# ESP32-S31 register map
Vendor: ESPRESSIF SYSTEMS (SHANGHAI) CO., LTD.; Series: ESP32 S-Series; File version: 1
CPU: RV32IMAFC r0p0, little endian, no MPU, FPU, 0 interrupt priority bits
Address unit: 32 bits
Registers are 32-bit, read-write, reset 0x0 unless marked. A register's access mark holds for its fields unless they carry their own. Offsets are from the block's base; [hi:lo] are bit positions; {n}, {i} and the like mark numbered series.

## DMA2D — DMA2D Peripheral
Base 0x20346000
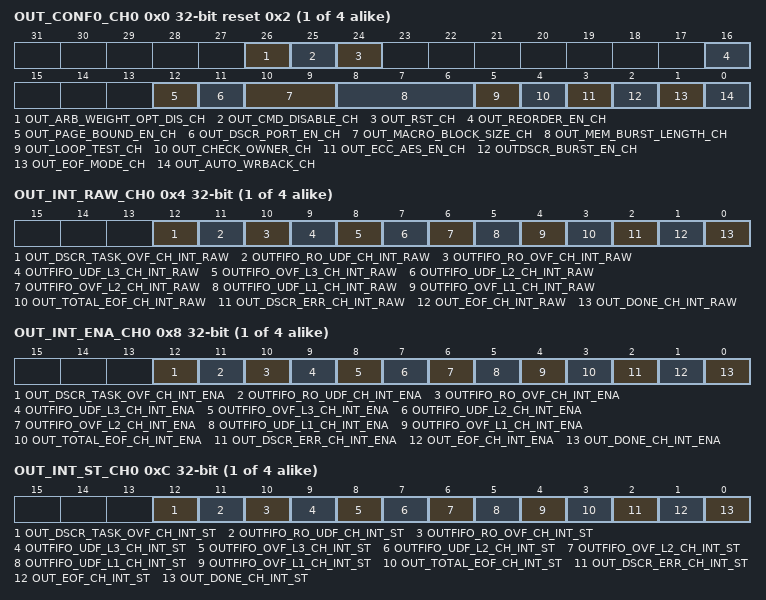
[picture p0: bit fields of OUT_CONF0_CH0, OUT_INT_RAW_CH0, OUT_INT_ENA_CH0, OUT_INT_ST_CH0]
{0x0+0x100*i} OUT_CONF0_CH{i} (i=0..3) reset 0x2 — Configures the tx direction of channel {i}
  [26] OUT_ARB_WEIGHT_OPT_DIS_CH — Set this bit to 1 to disable arbiter optimum weight function.
  [25] OUT_CMD_DISABLE_CH — Write 1 before reset and write 0 after reset
  [24] OUT_RST_CH — Write 1 then write 0 to this bit to reset TX channel
  [16] OUT_REORDER_EN_CH — Enable TX channel 0 macro block reorder when set to 1, only channel0 have this selection
  [12] OUT_PAGE_BOUND_EN_CH — Set this bit to 1 to make sure AXI read data don't cross the address boundary which define by mem_burst_length
  [11] OUT_DSCR_PORT_EN_CH — Set this bit to 1 to obtain descriptor from IP port
  [10:9] OUT_MACRO_BLOCK_SIZE_CH — Sel TX macro-block size 0: 8pixel*8pixel 1: 8pixel*16pixel 2: 16pixel*16pixel 3: no macro-block , only useful in mode 1 of the link descriptor
  [8:6] OUT_MEM_BURST_LENGTH_CH — Block size of Tx channel 0. 0: single 1: 16 bytes 2: 32 bytes 3: 64 bytes 4: 128 bytes
  [5] OUT_LOOP_TEST_CH — reserved
  [4] OUT_CHECK_OWNER_CH — Set this bit to enable checking the owner attribute of the link descriptor.
  [3] OUT_ECC_AES_EN_CH — When access address space is ecc/aes area, this bit should be set to 1. In this case, the start address of square should be 16-bit aligned. The width of square multiply byte number of one pixel should be 16-bit aligned.
  [2] OUTDSCR_BURST_EN_CH — Set this bit to 1 to enable INCR burst transfer for Tx channel 0 reading link descriptor when accessing internal SRAM.
  [1] OUT_EOF_MODE_CH — EOF flag generation mode when receiving data. 1: EOF flag for Tx channel 0 is generated when data need to read has been popped from FIFO in DMA
  [0] OUT_AUTO_WRBACK_CH — Set this bit to enable automatic outlink-writeback when all the data pointed by outlink descriptor has been received.
{0x4+0x100*i} OUT_INT_RAW_CH{i} (i=0..3) — Raw interrupt status of TX channel {i}
  [12] OUT_DSCR_TASK_OVF_CH_INT_RAW — The raw interrupt bit turns to high level when dscr ready task fifo is overflow.
  [11] OUTFIFO_RO_UDF_CH_INT_RAW — The raw interrupt bit turns to high level when reorder fifo is underflow.
  [10] OUTFIFO_RO_OVF_CH_INT_RAW — The raw interrupt bit turns to high level when reorder fifo is overflow.
  [9] OUTFIFO_UDF_L3_CH_INT_RAW — The raw interrupt bit turns to high level when fifo is underflow.
  [8] OUTFIFO_OVF_L3_CH_INT_RAW — The raw interrupt bit turns to high level when fifo is overflow.
  [7] OUTFIFO_UDF_L2_CH_INT_RAW — The raw interrupt bit turns to high level when fifo is underflow.
  [6] OUTFIFO_OVF_L2_CH_INT_RAW — The raw interrupt bit turns to high level when fifo is overflow.
  [5] OUTFIFO_UDF_L1_CH_INT_RAW — The raw interrupt bit turns to high level when fifo is underflow.
  [4] OUTFIFO_OVF_L1_CH_INT_RAW — The raw interrupt bit turns to high level when fifo is overflow.
  [3] OUT_TOTAL_EOF_CH_INT_RAW — The raw interrupt bit turns to high level when data corresponding a outlink (includes one link descriptor or few link descriptors) is transmitted out for Tx channel 0.
  [2] OUT_DSCR_ERR_CH_INT_RAW — The raw interrupt bit turns to high level when detecting outlink descriptor error, including owner error, the second and third word error of outlink descriptor for Tx channel 0.
  [1] OUT_EOF_CH_INT_RAW — The raw interrupt bit turns to high level when the last data pointed by one outlink descriptor has been read from memory for Tx channel 0.
  [0] OUT_DONE_CH_INT_RAW — The raw interrupt bit turns to high level when the last data pointed by one outlink descriptor has been transmitted to peripherals for Tx channel 0.
{0x8+0x100*i} OUT_INT_ENA_CH{i} (i=0..3) — Interrupt enable bits of TX channel {i}
  [12] OUT_DSCR_TASK_OVF_CH_INT_ENA — The interrupt enable bit for the OUT_DSCR_TASK_OVF_CH_INT interrupt.
  [11] OUTFIFO_RO_UDF_CH_INT_ENA — The interrupt enable bit for the OUTFIFO_RO_UDF_CH_INT interrupt.
  [10] OUTFIFO_RO_OVF_CH_INT_ENA — The interrupt enable bit for the OUTFIFO_RO_OVF_CH_INT interrupt.
  [9] OUTFIFO_UDF_L3_CH_INT_ENA — The interrupt enable bit for the OUTFIFO_UDF_L3_CH_INT interrupt.
  [8] OUTFIFO_OVF_L3_CH_INT_ENA — The interrupt enable bit for the OUTFIFO_OVF_L3_CH_INT interrupt.
  [7] OUTFIFO_UDF_L2_CH_INT_ENA — The interrupt enable bit for the OUTFIFO_UDF_L2_CH_INT interrupt.
  [6] OUTFIFO_OVF_L2_CH_INT_ENA — The interrupt enable bit for the OUTFIFO_OVF_L2_CH_INT interrupt.
  [5] OUTFIFO_UDF_L1_CH_INT_ENA — The interrupt enable bit for the OUTFIFO_UDF_L1_CH_INT interrupt.
  [4] OUTFIFO_OVF_L1_CH_INT_ENA — The interrupt enable bit for the OUTFIFO_OVF_L1_CH_INT interrupt.
  [3] OUT_TOTAL_EOF_CH_INT_ENA — The interrupt enable bit for the OUT_TOTAL_EOF_CH_INT interrupt.
  [2] OUT_DSCR_ERR_CH_INT_ENA — The interrupt enable bit for the OUT_DSCR_ERR_CH_INT interrupt.
  [1] OUT_EOF_CH_INT_ENA — The interrupt enable bit for the OUT_EOF_CH_INT interrupt.
  [0] OUT_DONE_CH_INT_ENA — The interrupt enable bit for the OUT_DONE_CH_INT interrupt.
{0xC+0x100*i} OUT_INT_ST_CH{i} (i=0..3) ro — Masked interrupt status of TX channel {i}
  [12] OUT_DSCR_TASK_OVF_CH_INT_ST — The raw interrupt status bit for the OUT_DSCR_TASK_OVF_CH_INT interrupt.
  [11] OUTFIFO_RO_UDF_CH_INT_ST — The raw interrupt status bit for the OUTFIFO_RO_UDF_CH_INT interrupt.
  [10] OUTFIFO_RO_OVF_CH_INT_ST — The raw interrupt status bit for the OUTFIFO_RO_OVF_CH_INT interrupt.
  [9] OUTFIFO_UDF_L3_CH_INT_ST — The raw interrupt status bit for the OUTFIFO_UDF_L3_CH_INT interrupt.
  [8] OUTFIFO_OVF_L3_CH_INT_ST — The raw interrupt status bit for the OUTFIFO_OVF_L3_CH_INT interrupt.
  [7] OUTFIFO_UDF_L2_CH_INT_ST — The raw interrupt status bit for the OUTFIFO_UDF_L2_CH_INT interrupt.
  [6] OUTFIFO_OVF_L2_CH_INT_ST — The raw interrupt status bit for the OUTFIFO_OVF_L2_CH_INT interrupt.
  [5] OUTFIFO_UDF_L1_CH_INT_ST — The raw interrupt status bit for the OUTFIFO_UDF_L1_CH_INT interrupt.
  [4] OUTFIFO_OVF_L1_CH_INT_ST — The raw interrupt status bit for the OUTFIFO_OVF_L1_CH_INT interrupt.
  [3] OUT_TOTAL_EOF_CH_INT_ST — The raw interrupt status bit for the OUT_TOTAL_EOF_CH_INT interrupt.
  [2] OUT_DSCR_ERR_CH_INT_ST — The raw interrupt status bit for the OUT_DSCR_ERR_CH_INT interrupt.
  [1] OUT_EOF_CH_INT_ST — The raw interrupt status bit for the OUT_EOF_CH_INT interrupt.
  [0] OUT_DONE_CH_INT_ST — The raw interrupt status bit for the OUT_DONE_CH_INT interrupt.
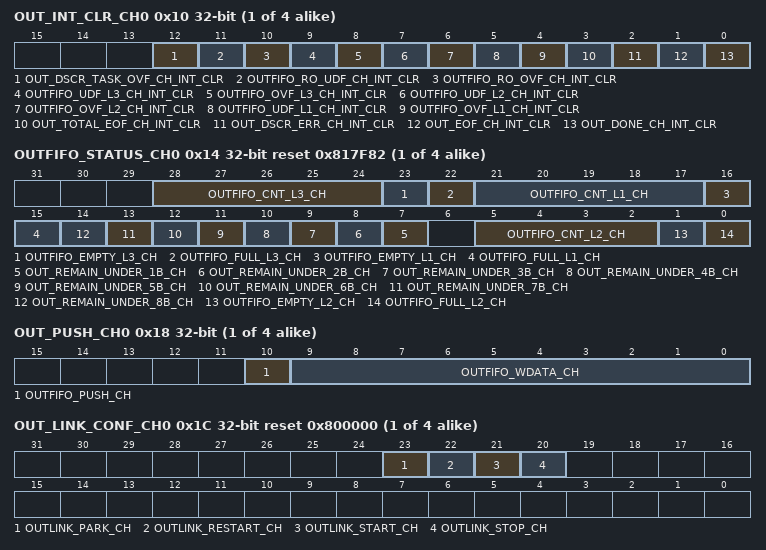
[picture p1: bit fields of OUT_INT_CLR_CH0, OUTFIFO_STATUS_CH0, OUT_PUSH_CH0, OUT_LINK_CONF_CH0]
{0x10+0x100*i} OUT_INT_CLR_CH{i} (i=0..3) wo — Interrupt clear bits of TX channel {i}
  [12] OUT_DSCR_TASK_OVF_CH_INT_CLR — Set this bit to clear the OUT_DSCR_TASK_OVF_CH_INT interrupt.
  [11] OUTFIFO_RO_UDF_CH_INT_CLR — Set this bit to clear the OUTFIFO_RO_UDF_CH_INT interrupt.
  [10] OUTFIFO_RO_OVF_CH_INT_CLR — Set this bit to clear the OUTFIFO_RO_OVF_CH_INT interrupt.
  [9] OUTFIFO_UDF_L3_CH_INT_CLR — Set this bit to clear the OUTFIFO_UDF_L3_CH_INT interrupt.
  [8] OUTFIFO_OVF_L3_CH_INT_CLR — Set this bit to clear the OUTFIFO_OVF_L3_CH_INT interrupt.
  [7] OUTFIFO_UDF_L2_CH_INT_CLR — Set this bit to clear the OUTFIFO_UDF_L2_CH_INT interrupt.
  [6] OUTFIFO_OVF_L2_CH_INT_CLR — Set this bit to clear the OUTFIFO_OVF_L2_CH_INT interrupt.
  [5] OUTFIFO_UDF_L1_CH_INT_CLR — Set this bit to clear the OUTFIFO_UDF_L1_CH_INT interrupt.
  [4] OUTFIFO_OVF_L1_CH_INT_CLR — Set this bit to clear the OUTFIFO_OVF_L1_CH_INT interrupt.
  [3] OUT_TOTAL_EOF_CH_INT_CLR — Set this bit to clear the OUT_TOTAL_EOF_CH_INT interrupt.
  [2] OUT_DSCR_ERR_CH_INT_CLR — Set this bit to clear the OUT_DSCR_ERR_CH_INT interrupt.
  [1] OUT_EOF_CH_INT_CLR — Set this bit to clear the OUT_EOF_CH_INT interrupt.
  [0] OUT_DONE_CH_INT_CLR — Set this bit to clear the OUT_DONE_CH_INT interrupt.
{0x14+0x100*i} OUTFIFO_STATUS_CH{i} (i=0..3) ro reset 0x817F82 — Represents the status of the tx fifo of channel {i}
  [28:24] OUTFIFO_CNT_L3_CH — The register stores the byte number of the data in Tx FIFO for Tx channel 0.
  [23] OUTFIFO_EMPTY_L3_CH — Tx FIFO empty signal for Tx channel 0.
  [22] OUTFIFO_FULL_L3_CH — Tx FIFO full signal for Tx channel 0.
  [21:17] OUTFIFO_CNT_L1_CH — The register stores the byte number of the data in Tx FIFO for Tx channel 0.
  [16] OUTFIFO_EMPTY_L1_CH — Tx FIFO empty signal for Tx channel 0.
  [15] OUTFIFO_FULL_L1_CH — Tx FIFO full signal for Tx channel 0.
  [n+6] OUT_REMAIN_UNDER_{n}B_CH (n=1..8) — reserved
  [5:2] OUTFIFO_CNT_L2_CH — The register stores the byte number of the data in Tx FIFO for Tx channel 0.
  [1] OUTFIFO_EMPTY_L2_CH — Tx FIFO empty signal for Tx channel 0.
  [0] OUTFIFO_FULL_L2_CH — Tx FIFO full signal for Tx channel 0.
{0x18+0x100*i} OUT_PUSH_CH{i} (i=0..3) — Configures the tx fifo of channel {i}
  [10] OUTFIFO_PUSH_CH — Set this bit to push data into DMA Tx FIFO.
  [9:0] OUTFIFO_WDATA_CH — This register stores the data that need to be pushed into DMA Tx FIFO.
{0x1C+0x100*i} OUT_LINK_CONF_CH{i} (i=0..3) access per field reset 0x800000 — Configures the tx descriptor operations of channel {i}
  [23] OUTLINK_PARK_CH ro — 1: the outlink descriptor's FSM is in idle state. 0: the outlink descriptor's FSM is working.
  [22] OUTLINK_RESTART_CH rw — Set this bit to restart a new outlink from the last address.
  [21] OUTLINK_START_CH rw — Set this bit to start dealing with the outlink descriptors.
  [20] OUTLINK_STOP_CH rw — Set this bit to stop dealing with the outlink descriptors.
{0x20+0x100*i} OUT_LINK_ADDR_CH{i} (i=0..3) — Configures the tx descriptor address of channel {i}
  [31:0] OUTLINK_ADDR_CH — This register stores the first outlink descriptor's address.
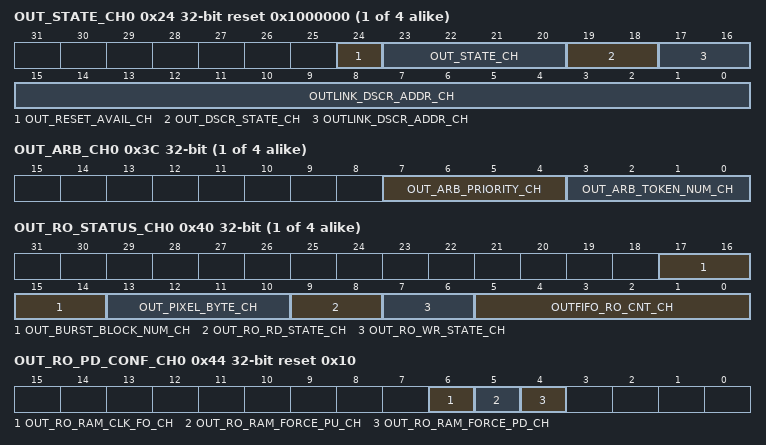
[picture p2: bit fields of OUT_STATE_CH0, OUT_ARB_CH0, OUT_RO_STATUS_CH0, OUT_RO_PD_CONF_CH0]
{0x24+0x100*i} OUT_STATE_CH{i} (i=0..3) ro reset 0x1000000 — Represents the working status of the tx descriptor of channel {i}
  [24] OUT_RESET_AVAIL_CH — This register indicate that if the channel reset is safety.
  [23:20] OUT_STATE_CH — This register stores the current control module state machine state.
  [19:18] OUT_DSCR_STATE_CH — This register stores the current descriptor state machine state.
  [17:0] OUTLINK_DSCR_ADDR_CH — This register stores the current outlink descriptor's address.
{0x28+0x100*i} OUT_EOF_DES_ADDR_CH{i} (i=0..3) ro — Represents the address associated with the outlink descriptor of channel {i}
  [31:0] OUT_EOF_DES_ADDR_CH — This register stores the address of the outlink descriptor when the EOF bit in this descriptor is 1.
{0x2C+0x100*i} OUT_DSCR_CH{i} (i=0..3) ro — Represents the address associated with the outlink descriptor of channel {i}
  [31:0] OUTLINK_DSCR_CH — The address of the next outlink descriptor address y.
{0x30+0x100*i} OUT_DSCR_BF0_CH{i} (i=0..3) ro — Represents the address associated with the outlink descriptor of channel {i}
  [31:0] OUTLINK_DSCR_BF0_CH — The address of the last outlink descriptor's next address y-1.
{0x34+0x100*i} OUT_DSCR_BF1_CH{i} (i=0..3) ro — Represents the address associated with the outlink descriptor of channel {i}
  [31:0] OUTLINK_DSCR_BF1_CH — The address of the second-to-last outlink descriptor's next address y-2.
{0x38+0x100*i} OUT_PERI_SEL_CH{i} (i=0..3) reset 0x7 — Configures the tx peripheral of channel {i}
  [2:0] OUT_PERI_SEL_CH — This register is used to select peripheral for Tx channel 0: jpeg 1: display-1 2: display-2 3: display-3 7: no choose
{0x3C+0x100*i} OUT_ARB_CH{i} (i=0..3) — Configures the tx arbiter of channel {i}
  [7:4] OUT_ARB_PRIORITY_CH — Set the priority of channel
  [3:0] OUT_ARB_TOKEN_NUM_CH — Set the max number of token count of arbiter
{0x40+0x100*i} OUT_RO_STATUS_CH{i} (i=0..3) ro — Represents the status of the tx reorder module of channel {i}
  [17:14] OUT_BURST_BLOCK_NUM_CH — the number of macro blocks contained in a burst of data at TX channel
  [13:10] OUT_PIXEL_BYTE_CH — the number of bytes contained in a pixel at TX channel 0: 1byte 1: 1.5bytes 2 : 2bytes 3: 2.5bytes 4: 3bytes 5: 4bytes
  [9:8] OUT_RO_RD_STATE_CH — The register stores the state of write ram of reorder
  [7:6] OUT_RO_WR_STATE_CH — The register stores the state of read ram of reorder
  [5:0] OUTFIFO_RO_CNT_CH — The register stores the byte number of the data in color convert Tx FIFO for channel 0.
0x44 OUT_RO_PD_CONF_CH0 reset 0x10 — Configures the tx reorder memory of channel 0
  [6] OUT_RO_RAM_CLK_FO_CH — 1: Force to open the clock and bypass the gate-clock when accessing the RAM in DMA. 0: A gate-clock will be used when accessing the RAM in DMA.
  [5] OUT_RO_RAM_FORCE_PU_CH — unused! dma reorder ram power up
  [4] OUT_RO_RAM_FORCE_PD_CH — unused! dma reorder ram power down
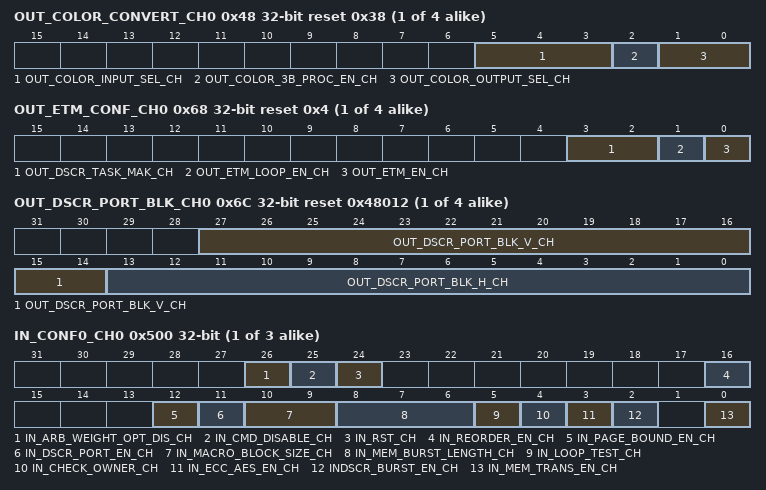
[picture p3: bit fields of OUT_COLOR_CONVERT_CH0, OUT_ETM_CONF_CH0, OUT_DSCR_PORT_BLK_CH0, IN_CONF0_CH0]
{0x48+0x100*i} OUT_COLOR_CONVERT_CH{i} (i=0..3) reset 0x38 — Configures the tx color convert of channel {i}
  [5:3] OUT_COLOR_INPUT_SEL_CH — Set first color convert process and input color type 0: RGB565 to RGB888 1: YUV422 to YUV444 2: Other 2byte/pixel type 3: Other 3byte/pixel type 7: disable color space convert
  [2] OUT_COLOR_3B_PROC_EN_CH — Enable generic color convert modlue between color input & color output, need to configure parameter.
  [1:0] OUT_COLOR_OUTPUT_SEL_CH — Set final color convert process and output type 0: RGB888 to RGB565 1: YUV444 to YUV422 2: output directly
{0x4C+0x100*i} OUT_SCRAMBLE_CH{i} (i=0..3) — Configures the tx scramble of channel {i}
  [2:0] OUT_SCRAMBLE_SEL_PRE_CH — Scramble data before color convert : 0 : BYTE2-1-0 1 : BYTE2-0-1 2 : BYTE1-0-2 3 : BYTE1-2-0 4 : BYTE0-2-1 5 : BYTE0-1-2
{0x50+0x100*i} OUT_COLOR_PARAM0_CH{i} (i=0..3) reset 0x12A — Configures the tx color convert parameter of channel {i}
  [20:0] OUT_COLOR_PARAM_H0_CH — Set first 2 parameter of most significant byte of pending 3 bytes
{0x54+0x100*i} OUT_COLOR_PARAM1_CH{i} (i=0..3) reset 0xC86D999 — Configures the tx color convert parameter of channel {i}
  [27:0] OUT_COLOR_PARAM_H1_CH — Set last 2 parameter of most significant byte of pending 3 bytes
{0x58+0x100*i} OUT_COLOR_PARAM2_CH{i} (i=0..3) reset 0x1E712A — Configures the tx color convert parameter of channel {i}
  [20:0] OUT_COLOR_PARAM_M0_CH — Set first 2 parameter of midium significant byte of pending 3 bytes
{0x5C+0x100*i} OUT_COLOR_PARAM3_CH{i} (i=0..3) reset 0x21E4F30 — Configures the tx color convert parameter of channel {i}
  [27:0] OUT_COLOR_PARAM_M1_CH — Set last 2 parameter of midium significant byte of pending 3 bytes
{0x60+0x100*i} OUT_COLOR_PARAM4_CH{i} (i=0..3) reset 0x8112A — Configures the tx color convert parameter of channel {i}
  [20:0] OUT_COLOR_PARAM_L0_CH — Set first 2 parameter of least significant byte of pending 3 bytes
{0x64+0x100*i} OUT_COLOR_PARAM5_CH{i} (i=0..3) reset 0xBAD3000 — Configures the tx color convert parameter of channel {i}
  [27:0] OUT_COLOR_PARAM_L1_CH — Set last 2 parameter of least significant byte of pending 3 bytes
{0x68+0x100*i} OUT_ETM_CONF_CH{i} (i=0..3) reset 0x4 — Configures the tx etm of channel {i}
  [3:2] OUT_DSCR_TASK_MAK_CH — Configures the maximum number of cacheable descriptors.
  [1] OUT_ETM_LOOP_EN_CH — Configures the enable of the descriptors loop etm function, 1 is enable.
  [0] OUT_ETM_EN_CH — Configures the enable of the etm function, 1 is enable.
{0x6C+0x100*i} OUT_DSCR_PORT_BLK_CH{i} (i=0..3) reset 0x48012 — Configures the tx block size in dscr port mode
  [27:14] OUT_DSCR_PORT_BLK_V_CH — Set the horizontal width of tx block size in dscr port mode
  [13:0] OUT_DSCR_PORT_BLK_H_CH — Set the vertical height of tx block size in dscr port mode
{0x500+0x100*i} IN_CONF0_CH{i} (i=0..2) — Configures the rx direction of channel {i}
  [26] IN_ARB_WEIGHT_OPT_DIS_CH — Set this bit to 1 to disable arbiter optimum weight function.
  [25] IN_CMD_DISABLE_CH — Write 1 before reset and write 0 after reset
  [24] IN_RST_CH — Write 1 then write 0 to this bit to reset Rx channel
  [16] IN_REORDER_EN_CH — Enable RX channel 0 macro block reorder when set to 1, only channel0 have this selection
  [12] IN_PAGE_BOUND_EN_CH — Set this bit to 1 to make sure AXI write data don't cross the address boundary which define by mem_burst_length
  [11] IN_DSCR_PORT_EN_CH — Set this bit to 1 to obtain descriptor from IP port
  [10:9] IN_MACRO_BLOCK_SIZE_CH — Sel RX macro-block size 0: 8pixel*8pixel 1: 8pixel*16pixel 2: 16pixel*16pixel 3: no macro-block , only useful in mode 1 of the link descriptor
  [8:6] IN_MEM_BURST_LENGTH_CH — Block size of Rx channel 0. 0: single 1: 16 bytes 2: 32 bytes 3: 64 bytes 4: 128 bytes
  [5] IN_LOOP_TEST_CH — reserved
  [4] IN_CHECK_OWNER_CH — Set this bit to enable checking the owner attribute of the link descriptor.
  [3] IN_ECC_AES_EN_CH — When access address space is ecc/aes area, this bit should be set to 1. In this case, the start address of square should be 16-bit aligned. The width of square multiply byte number of one pixel should be 16-bit aligned.
  [2] INDSCR_BURST_EN_CH — Set this bit to 1 to enable INCR burst transfer for Rx transmitting link descriptor when accessing SRAM.
  [0] IN_MEM_TRANS_EN_CH — enable memory trans of the same channel
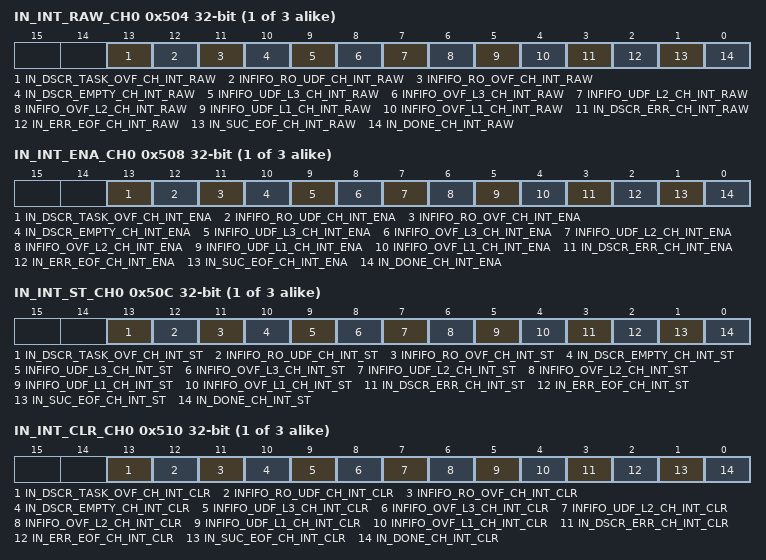
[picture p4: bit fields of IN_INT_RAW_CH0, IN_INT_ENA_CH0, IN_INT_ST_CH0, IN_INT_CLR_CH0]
{0x504+0x100*i} IN_INT_RAW_CH{i} (i=0..2) — Raw interrupt status of RX channel {i}
  [13] IN_DSCR_TASK_OVF_CH_INT_RAW — The raw interrupt bit turns to high level when dscr ready task fifo is overflow.
  [12] INFIFO_RO_UDF_CH_INT_RAW — The raw interrupt bit turns to high level when reorder fifo is underflow.
  [11] INFIFO_RO_OVF_CH_INT_RAW — The raw interrupt bit turns to high level when reorder fifo is overflow.
  [10] IN_DSCR_EMPTY_CH_INT_RAW — The raw interrupt bit turns to high level when the last descriptor is done but fifo also remain data.
  [9] INFIFO_UDF_L3_CH_INT_RAW — The raw interrupt bit turns to high level when fifo of Rx channel is underflow.
  [8] INFIFO_OVF_L3_CH_INT_RAW — The raw interrupt bit turns to high level when fifo of Rx channel is overflow.
  [7] INFIFO_UDF_L2_CH_INT_RAW — The raw interrupt bit turns to high level when fifo of Rx channel is underflow.
  [6] INFIFO_OVF_L2_CH_INT_RAW — The raw interrupt bit turns to high level when fifo of Rx channel is overflow.
  [5] INFIFO_UDF_L1_CH_INT_RAW — The raw interrupt bit turns to high level when fifo of Rx channel is underflow.
  [4] INFIFO_OVF_L1_CH_INT_RAW — The raw interrupt bit turns to high level when fifo of Rx channel is overflow.
  [3] IN_DSCR_ERR_CH_INT_RAW — The raw interrupt bit turns to high level when detecting inlink descriptor error, including owner error, the second and third word error of inlink descriptor for Rx channel 0.
  [2] IN_ERR_EOF_CH_INT_RAW — The raw interrupt bit turns to high level when the last data pointed by one inlink descriptor has been received and data error is detected
  [1] IN_SUC_EOF_CH_INT_RAW — The raw interrupt bit turns to high level when the last data pointed by one inlink descriptor has been received and no data error is detected for Rx channel 0.
  [0] IN_DONE_CH_INT_RAW — The raw interrupt bit turns to high level when the last data pointed by one inlink descriptor has been transmitted to peripherals for Rx channel 0.
{0x508+0x100*i} IN_INT_ENA_CH{i} (i=0..2) — Interrupt enable bits of RX channel {i}
  [13] IN_DSCR_TASK_OVF_CH_INT_ENA — The interrupt enable bit for the IN_DSCR_TASK_OVF_CH_INT interrupt.
  [12] INFIFO_RO_UDF_CH_INT_ENA — The interrupt enable bit for the INFIFO_RO_UDF_CH_INT interrupt.
  [11] INFIFO_RO_OVF_CH_INT_ENA — The interrupt enable bit for the INFIFO_RO_OVF_CH_INT interrupt.
  [10] IN_DSCR_EMPTY_CH_INT_ENA — The interrupt enable bit for the IN_DSCR_EMPTY_CH_INT interrupt.
  [9] INFIFO_UDF_L3_CH_INT_ENA — The interrupt enable bit for the INFIFO_UDF_L3_CH_INT interrupt.
  [8] INFIFO_OVF_L3_CH_INT_ENA — The interrupt enable bit for the INFIFO_OVF_L3_CH_INT interrupt.
  [7] INFIFO_UDF_L2_CH_INT_ENA — The interrupt enable bit for the INFIFO_UDF_L2_CH_INT interrupt.
  [6] INFIFO_OVF_L2_CH_INT_ENA — The interrupt enable bit for the INFIFO_OVF_L2_CH_INT interrupt.
  [5] INFIFO_UDF_L1_CH_INT_ENA — The interrupt enable bit for the INFIFO_UDF_L1_CH_INT interrupt.
  [4] INFIFO_OVF_L1_CH_INT_ENA — The interrupt enable bit for the INFIFO_OVF_L1_CH_INT interrupt.
  [3] IN_DSCR_ERR_CH_INT_ENA — The interrupt enable bit for the IN_DSCR_ERR_CH_INT interrupt.
  [2] IN_ERR_EOF_CH_INT_ENA — The interrupt enable bit for the IN_ERR_EOF_CH_INT interrupt.
  [1] IN_SUC_EOF_CH_INT_ENA — The interrupt enable bit for the IN_SUC_EOF_CH_INT interrupt.
  [0] IN_DONE_CH_INT_ENA — The interrupt enable bit for the IN_DONE_CH_INT interrupt.
{0x50C+0x100*i} IN_INT_ST_CH{i} (i=0..2) ro — Masked interrupt status of RX channel {i}
  [13] IN_DSCR_TASK_OVF_CH_INT_ST — The raw interrupt status bit for the IN_DSCR_TASK_OVF_CH_INT interrupt.
  [12] INFIFO_RO_UDF_CH_INT_ST — The raw interrupt status bit for the INFIFO_RO_UDF_CH_INT interrupt.
  [11] INFIFO_RO_OVF_CH_INT_ST — The raw interrupt status bit for the INFIFO_RO_OVF_CH_INT interrupt.
  [10] IN_DSCR_EMPTY_CH_INT_ST — The raw interrupt status bit for the IN_DSCR_EMPTY_CH_INT interrupt.
  [9] INFIFO_UDF_L3_CH_INT_ST — The raw interrupt status bit for the INFIFO_UDF_L3_CH_INT interrupt.
  [8] INFIFO_OVF_L3_CH_INT_ST — The raw interrupt status bit for the INFIFO_OVF_L3_CH_INT interrupt.
  [7] INFIFO_UDF_L2_CH_INT_ST — The raw interrupt status bit for the INFIFO_UDF_L2_CH_INT interrupt.
  [6] INFIFO_OVF_L2_CH_INT_ST — The raw interrupt status bit for the INFIFO_OVF_L2_CH_INT interrupt.
  [5] INFIFO_UDF_L1_CH_INT_ST — The raw interrupt status bit for the INFIFO_UDF_L1_CH_INT interrupt.
  [4] INFIFO_OVF_L1_CH_INT_ST — The raw interrupt status bit for the INFIFO_OVF_L1_CH_INT interrupt.
  [3] IN_DSCR_ERR_CH_INT_ST — The raw interrupt status bit for the IN_DSCR_ERR_CH_INT interrupt.
  [2] IN_ERR_EOF_CH_INT_ST — The raw interrupt status bit for the IN_ERR_EOF_CH_INT interrupt.
  [1] IN_SUC_EOF_CH_INT_ST — The raw interrupt status bit for the IN_SUC_EOF_CH_INT interrupt.
  [0] IN_DONE_CH_INT_ST — The raw interrupt status bit for the IN_DONE_CH_INT interrupt.
{0x510+0x100*i} IN_INT_CLR_CH{i} (i=0..2) wo — Interrupt clear bits of RX channel {i}
  [13] IN_DSCR_TASK_OVF_CH_INT_CLR — Set this bit to clear the IN_DSCR_TASK_OVF_CH_INT interrupt.
  [12] INFIFO_RO_UDF_CH_INT_CLR — Set this bit to clear the INFIFO_RO_UDF_CH_INT interrupt.
  [11] INFIFO_RO_OVF_CH_INT_CLR — Set this bit to clear the INFIFO_RO_OVF_CH_INT interrupt.
  [10] IN_DSCR_EMPTY_CH_INT_CLR — Set this bit to clear the IN_DSCR_EMPTY_CH_INT interrupt.
  [9] INFIFO_UDF_L3_CH_INT_CLR — Set this bit to clear the INFIFO_UDF_L3_CH_INT interrupt.
  [8] INFIFO_OVF_L3_CH_INT_CLR — Set this bit to clear the INFIFO_OVF_L3_CH_INT interrupt.
  [7] INFIFO_UDF_L2_CH_INT_CLR — Set this bit to clear the INFIFO_UDF_L2_CH_INT interrupt.
  [6] INFIFO_OVF_L2_CH_INT_CLR — Set this bit to clear the INFIFO_OVF_L2_CH_INT interrupt.
  [5] INFIFO_UDF_L1_CH_INT_CLR — Set this bit to clear the INFIFO_UDF_L1_CH_INT interrupt.
  [4] INFIFO_OVF_L1_CH_INT_CLR — Set this bit to clear the INFIFO_OVF_L1_CH_INT interrupt.
  [3] IN_DSCR_ERR_CH_INT_CLR — Set this bit to clear the INDSCR_ERR_CH_INT interrupt.
  [2] IN_ERR_EOF_CH_INT_CLR — Set this bit to clear the IN_ERR_EOF_CH_INT interrupt.
  [1] IN_SUC_EOF_CH_INT_CLR — Set this bit to clear the IN_SUC_EOF_CH_INT interrupt.
  [0] IN_DONE_CH_INT_CLR — Set this bit to clear the IN_DONE_CH_INT interrupt.
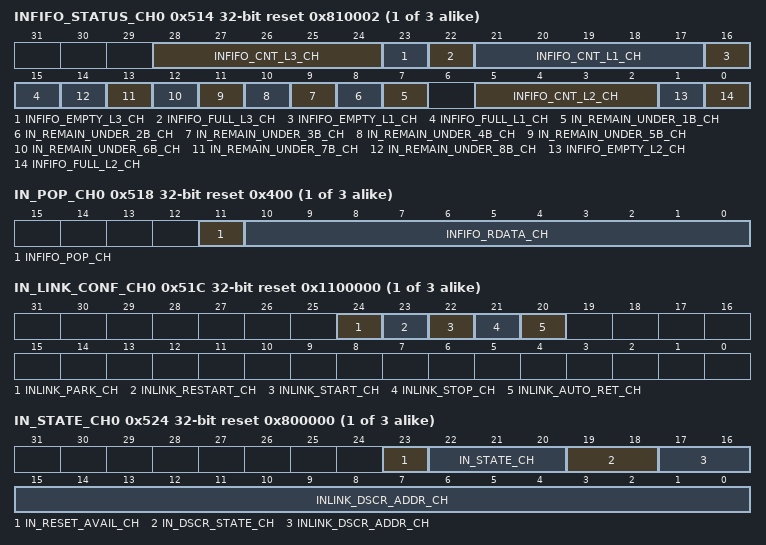
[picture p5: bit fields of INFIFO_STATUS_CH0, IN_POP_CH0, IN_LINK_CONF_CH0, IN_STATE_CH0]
{0x514+0x100*i} INFIFO_STATUS_CH{i} (i=0..2) ro reset 0x810002 — Represents the status of the rx fifo of channel {i}
  [28:24] INFIFO_CNT_L3_CH — The register stores the byte number of the data in Rx FIFO for Rx channel 0.
  [23] INFIFO_EMPTY_L3_CH — Rx FIFO empty signal for Rx channel 0.
  [22] INFIFO_FULL_L3_CH — Rx FIFO full signal for Rx channel 0.
  [21:17] INFIFO_CNT_L1_CH — The register stores the byte number of the data in Rx FIFO for Rx channel 0.
  [16] INFIFO_EMPTY_L1_CH — Rx FIFO empty signal for Rx channel 0.
  [15] INFIFO_FULL_L1_CH — Rx FIFO full signal for Rx channel 0.
  [n+6] IN_REMAIN_UNDER_{n}B_CH (n=1..8) — reserved
  [5:2] INFIFO_CNT_L2_CH — The register stores the byte number of the data in Rx FIFO for Rx channel.
  [1] INFIFO_EMPTY_L2_CH — Rx FIFO empty signal for Rx channel.
  [0] INFIFO_FULL_L2_CH — Rx FIFO full signal for Rx channel.
{0x518+0x100*i} IN_POP_CH{i} (i=0..2) access per field reset 0x400 — Configures the rx fifo of channel {i}
  [11] INFIFO_POP_CH rw — Set this bit to pop data from DMA Rx FIFO.
  [10:0] INFIFO_RDATA_CH ro — This register stores the data popping from DMA Rx FIFO.
{0x51C+0x100*i} IN_LINK_CONF_CH{i} (i=0..2) access per field reset 0x1100000 — Configures the rx descriptor operations of channel {i}
  [24] INLINK_PARK_CH ro — 1: the inlink descriptor's FSM is in idle state. 0: the inlink descriptor's FSM is working.
  [23] INLINK_RESTART_CH rw — Set this bit to mount a new inlink descriptor.
  [22] INLINK_START_CH rw — Set this bit to start dealing with the inlink descriptors.
  [21] INLINK_STOP_CH rw — Set this bit to stop dealing with the inlink descriptors.
  [20] INLINK_AUTO_RET_CH rw — Set this bit to return to current inlink descriptor's address, when there are some errors in current receiving data.
{0x520+0x100*i} IN_LINK_ADDR_CH{i} (i=0..2) — Configures the rx descriptor address of channel {i}
  [31:0] INLINK_ADDR_CH — This register stores the first inlink descriptor's address.
{0x524+0x100*i} IN_STATE_CH{i} (i=0..2) ro reset 0x800000 — Represents the working status of the rx descriptor of channel {i}
  [23] IN_RESET_AVAIL_CH — This register indicate that if the channel reset is safety.
  [22:20] IN_STATE_CH — reserved
  [19:18] IN_DSCR_STATE_CH — reserved
  [17:0] INLINK_DSCR_ADDR_CH — This register stores the current inlink descriptor's address.
{0x528+0x100*i} IN_SUC_EOF_DES_ADDR_CH{i} (i=0..2) ro — Represents the address associated with the inlink descriptor of channel {i}
  [31:0] IN_SUC_EOF_DES_ADDR_CH — This register stores the address of the inlink descriptor when the EOF bit in this descriptor is 1.
{0x52C+0x100*i} IN_ERR_EOF_DES_ADDR_CH{i} (i=0..2) ro — Represents the address associated with the inlink descriptor of channel {i}
  [31:0] IN_ERR_EOF_DES_ADDR_CH — This register stores the address of the inlink descriptor when there are some errors in current receiving data.
{0x530+0x100*i} IN_DSCR_CH{i} (i=0..2) ro — Represents the address associated with the inlink descriptor of channel {i}
  [31:0] INLINK_DSCR_CH — The address of the next inlink descriptor address x.
{0x534+0x100*i} IN_DSCR_BF0_CH{i} (i=0..2) ro — Represents the address associated with the inlink descriptor of channel {i}
  [31:0] INLINK_DSCR_BF0_CH — The address of the last inlink descriptor's next address x-1.
{0x538+0x100*i} IN_DSCR_BF1_CH{i} (i=0..2) ro — Represents the address associated with the inlink descriptor of channel {i}
  [31:0] INLINK_DSCR_BF1_CH — The address of the second-to-last inlink descriptor's next address x-2.
{0x53C+0x100*i} IN_PERI_SEL_CH{i} (i=0..2) reset 0x7 — Configures the rx peripheral of channel {i}
  [2:0] IN_PERI_SEL_CH — This register is used to select peripheral for Rx channel 0: jpeg 1: display-1 2: display-2 7: no choose
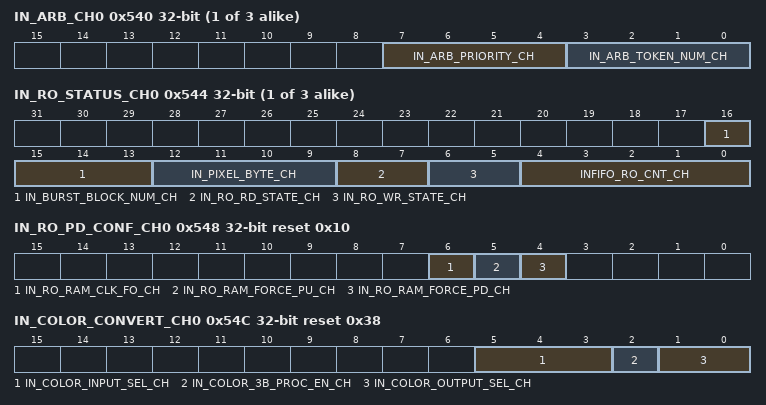
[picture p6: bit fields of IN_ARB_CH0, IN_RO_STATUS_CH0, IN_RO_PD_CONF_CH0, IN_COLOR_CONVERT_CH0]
{0x540+0x100*i} IN_ARB_CH{i} (i=0..2) — Configures the rx arbiter of channel {i}
  [7:4] IN_ARB_PRIORITY_CH — Set the priority of channel
  [3:0] IN_ARB_TOKEN_NUM_CH — Set the max number of token count of arbiter
{0x544+0x100*i} IN_RO_STATUS_CH{i} (i=0..2) ro — Represents the status of the rx reorder module of channel {i}
  [16:13] IN_BURST_BLOCK_NUM_CH — the number of macro blocks contained in a burst of data at RX channel
  [12:9] IN_PIXEL_BYTE_CH — the number of bytes contained in a pixel at RX channel 0: 1byte 1: 1.5bytes 2 : 2bytes 3: 2.5bytes 4: 3bytes 5: 4bytes
  [8:7] IN_RO_RD_STATE_CH — The register stores the state of write ram of reorder
  [6:5] IN_RO_WR_STATE_CH — The register stores the state of read ram of reorder
  [4:0] INFIFO_RO_CNT_CH — The register stores the byte number of the data in color convert Rx FIFO for channel 0.
0x548 IN_RO_PD_CONF_CH0 reset 0x10 — Configures the rx reorder memory of channel 0
  [6] IN_RO_RAM_CLK_FO_CH — 1: Force to open the clock and bypass the gate-clock when accessing the RAM in DMA. 0: A gate-clock will be used when accessing the RAM in DMA.
  [5] IN_RO_RAM_FORCE_PU_CH — unused! dma reorder ram power up
  [4] IN_RO_RAM_FORCE_PD_CH — unused! dma reorder ram power down
0x54C IN_COLOR_CONVERT_CH0 reset 0x38 — Configures the Rx color convert of channel 0
  [5:3] IN_COLOR_INPUT_SEL_CH — Set first color convert process and input color type 0: YUV422/420 to YUV444 1: YUV422 2: YUV444/420 7: disable color space convert
  [2] IN_COLOR_3B_PROC_EN_CH — Enable generic color convert modlue between color input & color output, need to configure parameter.
  [1:0] IN_COLOR_OUTPUT_SEL_CH — Set final color convert process and output type 0: RGB888 to RGB565 1: output directly 2: YUV444 to YUV422 3: YUV444 to YUV420
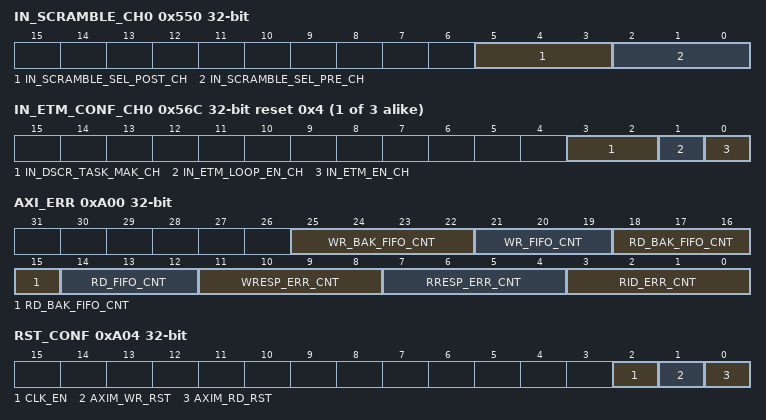
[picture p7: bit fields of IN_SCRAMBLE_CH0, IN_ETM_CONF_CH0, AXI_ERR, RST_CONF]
0x550 IN_SCRAMBLE_CH0 — Configures the rx scramble of channel 0
  [5:3] IN_SCRAMBLE_SEL_POST_CH — Scramble data after color convert : 0 : BYTE2-1-0 1 : BYTE2-0-1 2 : BYTE1-0-2 3 : BYTE1-2-0 4 : BYTE0-2-1 5 : BYTE0-1-2
  [2:0] IN_SCRAMBLE_SEL_PRE_CH — Scramble data before color convert : 0 : BYTE2-1-0 1 : BYTE2-0-1 2 : BYTE1-0-2 3 : BYTE1-2-0 4 : BYTE0-2-1 5 : BYTE0-1-2
0x554 IN_COLOR_PARAM0_CH0 reset 0x12A — Configures the rx color convert parameter of channel 0
  [20:0] IN_COLOR_PARAM_H0_CH — Set first 2 parameter of most significant byte of pending 3 bytes
0x558 IN_COLOR_PARAM1_CH0 reset 0xC86D999 — Configures the rx color convert parameter of channel 0
  [27:0] IN_COLOR_PARAM_H1_CH — Set last 2 parameter of most significant byte of pending 3 bytes
0x55C IN_COLOR_PARAM2_CH0 reset 0x1E712A — Configures the rx color convert parameter of channel 0
  [20:0] IN_COLOR_PARAM_M0_CH — Set first 2 parameter of midium significant byte of pending 3 bytes
0x560 IN_COLOR_PARAM3_CH0 reset 0x21E4F30 — Configures the rx color convert parameter of channel 0
  [27:0] IN_COLOR_PARAM_M1_CH — Set last 2 parameter of midium significant byte of pending 3 bytes
0x564 IN_COLOR_PARAM4_CH0 reset 0x8112A — Configures the rx color convert parameter of channel 0
  [20:0] IN_COLOR_PARAM_L0_CH — Set first 2 parameter of least significant byte of pending 3 bytes
0x568 IN_COLOR_PARAM5_CH0 reset 0xBAD3000 — Configures the rx color convert parameter of channel 0
  [27:0] IN_COLOR_PARAM_L1_CH — Set last 2 parameter of least significant byte of pending 3 bytes
{0x56C+0x100*i} IN_ETM_CONF_CH{i} (i=0..2) reset 0x4 — Configures the rx etm of channel {i}
  [3:2] IN_DSCR_TASK_MAK_CH — Configures the maximum number of cacheable descriptors.
  [1] IN_ETM_LOOP_EN_CH — Configures the enable of the descriptors loop etm function, 1 is enable.
  [0] IN_ETM_EN_CH — Configures the enable of the etm function, 1 is enable.
0xA00 AXI_ERR ro — Represents the status of th axi bus
  [25:22] WR_BAK_FIFO_CNT — AXI write backup cmd fifo remain cmd count
  [21:19] WR_FIFO_CNT — AXI write cmd fifo remain cmd count
  [18:15] RD_BAK_FIFO_CNT — AXI read backup cmd fifo remain cmd count
  [14:12] RD_FIFO_CNT — AXI read cmd fifo remain cmd count
  [11:8] WRESP_ERR_CNT — AXI write resp err cnt
  [7:4] RRESP_ERR_CNT — AXI read resp err cnt
  [3:0] RID_ERR_CNT — AXI read id err cnt
0xA04 RST_CONF — Configures the reset of axi
  [2] CLK_EN — 1'h1: Force clock on for register. 1'h0: Support clock only when application writes registers.
  [1] AXIM_WR_RST — Write 1 then write 0 to this bit to reset axi master write data FIFO.
  [0] AXIM_RD_RST — Write 1 then write 0 to this bit to reset axi master read data FIFO.
0xA08 INTR_MEM_START_ADDR — The start address of accessible address space.
  [31:0] ACCESS_INTR_MEM_START_ADDR
0xA0C INTR_MEM_END_ADDR reset 0xFFFFFFFF — The end address of accessible address space.
  [31:0] ACCESS_INTR_MEM_END_ADDR — The end address of accessible address space. The access address beyond this range would lead to descriptor error.
0xA10 EXTR_MEM_START_ADDR — The start address of accessible address space.
  [31:0] ACCESS_EXTR_MEM_START_ADDR
0xA14 EXTR_MEM_END_ADDR reset 0xFFFFFFFF — The end address of accessible address space.
  [31:0] ACCESS_EXTR_MEM_END_ADDR — The end address of accessible address space. The access address beyond this range would lead to descriptor error.
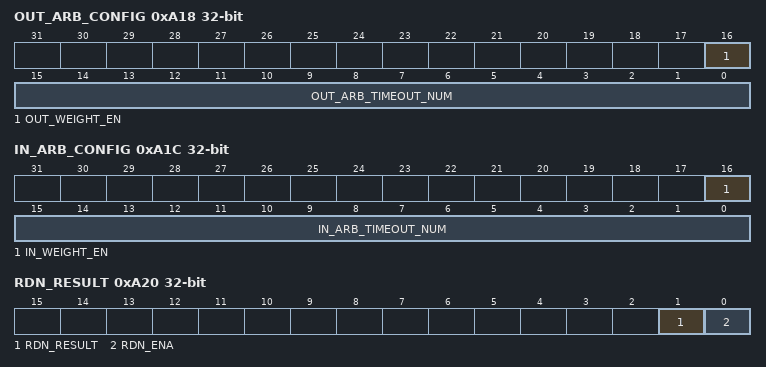
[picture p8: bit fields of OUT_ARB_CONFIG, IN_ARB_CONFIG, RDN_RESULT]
0xA18 OUT_ARB_CONFIG — Configures the tx arbiter
  [16] OUT_WEIGHT_EN — reserved
  [15:0] OUT_ARB_TIMEOUT_NUM — Set the max number of timeout count of arbiter
0xA1C IN_ARB_CONFIG — Configures the rx arbiter
  [16] IN_WEIGHT_EN — reserved
  [15:0] IN_ARB_TIMEOUT_NUM — Set the max number of timeout count of arbiter
0xA20 RDN_RESULT access per field — reserved
  [1] RDN_RESULT ro — reserved
  [0] RDN_ENA rw — reserved
0xA24 RDN_ECO_HIGH reset 0xFFFFFFFF — reserved
  [31:0] RDN_ECO_HIGH — The start address of accessible address space.
0xA28 RDN_ECO_LOW — reserved
  [31:0] RDN_ECO_LOW — The start address of accessible address space.
0xA2C DATE reset 0x2306190 — register version.
